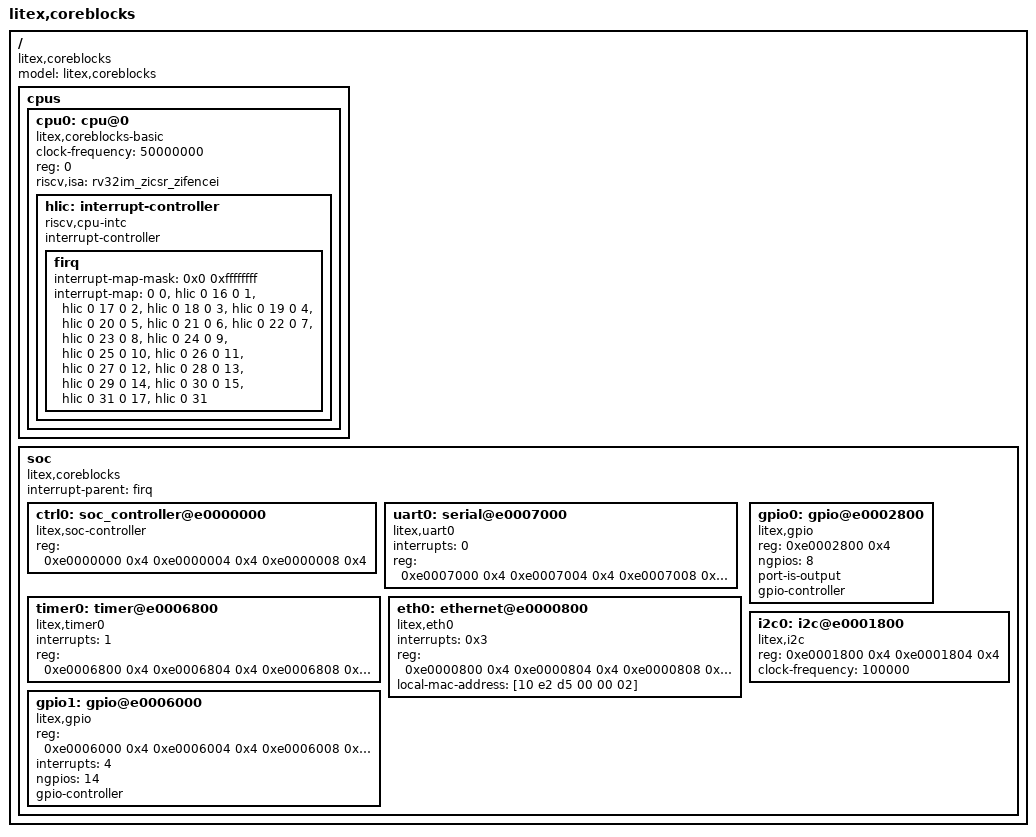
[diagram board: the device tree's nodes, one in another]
/*
 * Copyright (c) 2024 Piotr Wegrzyn (Kuznia Rdzeni)
 *
 * SPDX-License-Identifier: Apache-2.0
 */

/ {
	#address-cells = <1>;
	#size-cells = <1>;
	compatible = "litex,coreblocks", "litex-dev";
	model = "litex,coreblocks";

	cpus {
		#address-cells = <1>;
		#size-cells = <0>;
		cpu0: cpu@0 {
			clock-frequency = <50000000>;
			compatible = "litex,coreblocks-basic", "riscv";
			device_type = "cpu";
			reg = <0>;
			riscv,isa = "rv32im_zicsr_zifencei";
			status = "okay";

			hlic: interrupt-controller {
				compatible = "riscv,cpu-intc";
				#address-cells = <1>;
				#interrupt-cells = <1>;
				interrupt-controller;
				firq: firq {
					#address-cells = <1>;
					interrupt-map-mask = <0x0 0xffffffff>;
					interrupt-map = <
						0  0 &hlic 0 16
						0  1 &hlic 0 17
						0  2 &hlic 0 18
						0  3 &hlic 0 19
						0  4 &hlic 0 20
						0  5 &hlic 0 21
						0  6 &hlic 0 22
						0  7 &hlic 0 23
						0  8 &hlic 0 24
						0  9 &hlic 0 25
						0 10 &hlic 0 26
						0 11 &hlic 0 27
						0 12 &hlic 0 28
						0 13 &hlic 0 29
						0 14 &hlic 0 30
						0 15 &hlic 0 31
						0 17 &hlic 0 31
					>;
					#interrupt-cells = <1>;
				};
			};

		};
	};
	soc {
		#address-cells = <1>;
		#size-cells = <1>;
		compatible = "litex,coreblocks";
		interrupt-parent = <&firq>;
		ranges;
		ctrl0: soc_controller@e0000000 {
			compatible = "litex,soc-controller";
			reg =  <0xe0000000 0x4
				0xe0000004 0x4
				0xe0000008 0x4>;
			reg-names = "reset",
				"scratch",
				"bus_errors";
		};
		uart0: serial@e0007000 {
			compatible = "litex,uart0";
			interrupts = <0>;
			reg =  <0xe0007000 0x4
				0xe0007004 0x4
				0xe0007008 0x4
				0xe000700c 0x4
				0xe0007010 0x4
				0xe0007014 0x4
				0xe0007018 0x4
				0xe000701c 0x4>;
			reg-names =
				"rxtx",
				"txfull",
				"rxempty",
				"ev_status",
				"ev_pending",
				"ev_enable",
				"txempty",
				"rxfull";
		};
		timer0: timer@e0006800 {
			compatible = "litex,timer0";
			interrupts = <1>;
			reg =  <0xe0006800 0x4
				0xe0006804 0x4
				0xe0006808 0x4
				0xe000680c 0x4
				0xe0006810 0x4
				0xe0006814 0x4
				0xe0006818 0x4
				0xe000681c 0x4
				0xe0006e00 0x4
				0xe0006e04 0x8>;
			reg-names =
				"load",
				"reload",
				"en",
				"update_value",
				"value",
				"ev_status",
				"ev_pending",
				"ev_enable",
				"uptime_latch",
				"uptime_cycles";
		};
		eth0: ethernet@e0000800 {
			compatible = "litex,eth0";
			interrupts = <0x3>;
			reg =  <0xe0000800 0x4
				0xe0000804 0x4
				0xe0000808 0x4
				0xe000080c 0x4
				0xe0000810 0x4
				0xe0000814 0x4
				0xe0000818 0x4
				0xe000081c 0x4
				0xe0000e00 0x4
				0xe0000e04 0x4
				0xe0000e08 0x4
				0xe0000e0c 0x4
				0xe0000830 0x4
				0xe0000834 0x4
				0xe8000000 0x2000>;
			local-mac-address = [10 e2 d5 00 00 02];
			reg-names = "rx_slot",
				"rx_length",
				"rx_errors",
				"rx_ev_status",
				"rx_ev_pending",
				"rx_ev_enable",
				"tx_start",
				"tx_ready",
				"tx_level",
				"tx_slot",
				"tx_length",
				"tx_ev_status",
				"tx_ev_pending",
				"tx_ev_enable",
				"buffers";
		};
		gpio0: gpio@e0002800 {
			compatible = "litex,gpio";
			reg = <0xe0002800 0x4>;
			reg-names = "control";
			ngpios = <8>;
			port-is-output;
			gpio-controller;
			#gpio-cells = <2>;
		};
		gpio1: gpio@e0006000 {
			compatible = "litex,gpio";
			reg =  <0xe0006000 0x4
				0xe0006004 0x4
				0xe0006008 0x4
				0xe0006010 0x4
				0xe0006014 0x4>;
			interrupts = <4>;
			reg-names = "base",
				"irq_mode",
				"irq_edge",
				"irq_pend",
				"irq_en";
			ngpios = <14>;
			gpio-controller;
			#gpio-cells = <2>;
		};
		i2c0: i2c@e0001800 {
		    reg = <0xe0001800 0x4
			   0xe0001804 0x4>;
		    reg-names = "write",
				"read";
			clock-frequency = <100000>;
			compatible = "litex,i2c";

			#address-cells = <1>;
			#size-cells = <0>;

		};
	};
};
